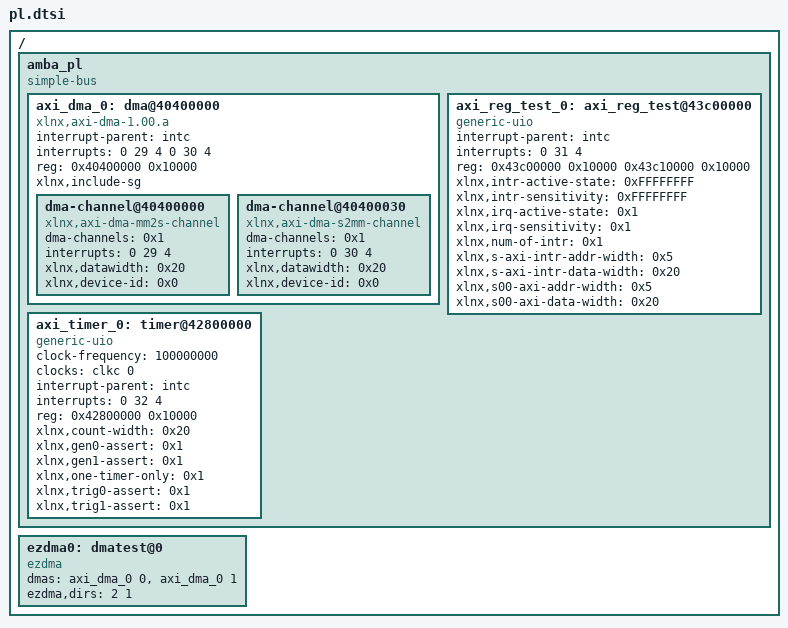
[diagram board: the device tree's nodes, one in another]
/*
 * CAUTION: This file is automatically generated by Xilinx.
 * Version:  
 * Today is: Thu Nov 17 16:30:03 2016
*/


/ {
	amba_pl: amba_pl {
		#address-cells = <1>;
		#size-cells = <1>;
		compatible = "simple-bus";
		ranges ;
		axi_dma_0: dma@40400000 {
			#dma-cells = <1>;
			compatible = "xlnx,axi-dma-1.00.a";
			interrupt-parent = <&intc>;
			interrupts = <0 29 4 0 30 4>;
			reg = <0x40400000 0x10000>;
			xlnx,include-sg ;
			dma-channel@40400000 {
				compatible = "xlnx,axi-dma-mm2s-channel";
				dma-channels = <0x1>;
				interrupts = <0 29 4>;
				xlnx,datawidth = <0x20>;
				xlnx,device-id = <0x0>;
			};
			dma-channel@40400030 {
				compatible = "xlnx,axi-dma-s2mm-channel";
				dma-channels = <0x1>;
				interrupts = <0 30 4>;
				xlnx,datawidth = <0x20>;
				xlnx,device-id = <0x0>;
			};
		};
		axi_reg_test_0: axi_reg_test@43c00000 {
			compatible = "generic-uio";
			interrupt-parent = <&intc>;
			interrupts = <0 31 4>;
			reg = <0x43c00000 0x10000 0x43c10000 0x10000>;
			xlnx,intr-active-state = <0xFFFFFFFF>;
			xlnx,intr-sensitivity = <0xFFFFFFFF>;
			xlnx,irq-active-state = <0x1>;
			xlnx,irq-sensitivity = <0x1>;
			xlnx,num-of-intr = <0x1>;
			xlnx,s-axi-intr-addr-width = <0x5>;
			xlnx,s-axi-intr-data-width = <0x20>;
			xlnx,s00-axi-addr-width = <0x5>;
			xlnx,s00-axi-data-width = <0x20>;
		};
		axi_timer_0: timer@42800000 {
			clock-frequency = <100000000>;
			clock-names = "ref_clk";
			clocks = <&clkc 0>;
			compatible = "generic-uio";
			interrupt-parent = <&intc>;
			interrupts = <0 32 4>;
			reg = <0x42800000 0x10000>;
			xlnx,count-width = <0x20>;
			xlnx,gen0-assert = <0x1>;
			xlnx,gen1-assert = <0x1>;
			xlnx,one-timer-only = <0x1>;
			xlnx,trig0-assert = <0x1>;
			xlnx,trig1-assert = <0x1>;
		};
	};
    ezdma0: dmatest@0 {
	compatible = "ezdma";

	dmas = <&axi_dma_0 0 &axi_dma_0 1>;
	dma-names = "loop_tx", "loop_rx";   // used when obtaining reference to above DMA core using dma_request_slave_channel()
	ezdma,dirs = <2 1>;                 // direction of DMA channel: 1 = RX (dev->cpu), 2 = TX (cpu->dev)
    };
};
